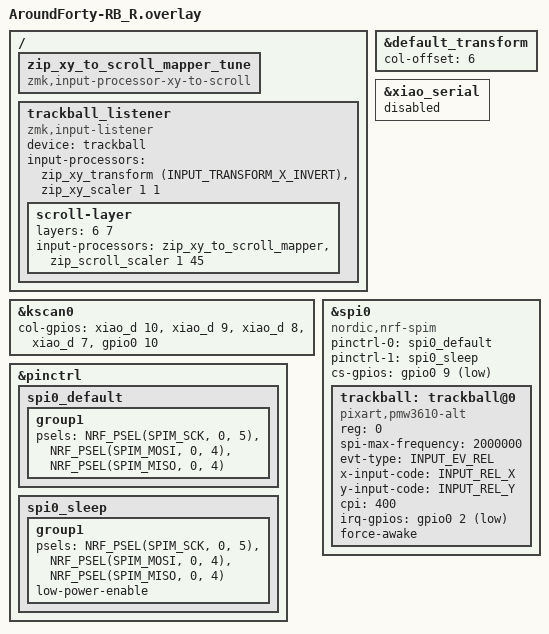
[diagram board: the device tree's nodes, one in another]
#include "AroundForty-RB.dtsi"
#include <dt-bindings/zmk/pointing.h>
#include <dt-bindings/zmk/input_transform.h>
#include <input/processors.dtsi>
#include <zephyr/dt-bindings/input/input-event-codes.h>

&default_transform {
    col-offset = <6>;
};

&kscan0 {
    col-gpios
        = <&xiao_d 10 GPIO_ACTIVE_HIGH>
        , <&xiao_d  9 GPIO_ACTIVE_HIGH>
        , <&xiao_d  8 GPIO_ACTIVE_HIGH>
        , <&xiao_d  7 GPIO_ACTIVE_HIGH>
        , <&gpio0  10 GPIO_ACTIVE_HIGH>
        ;
};

/ {
    /*
     * 将来スクロール方向を変えたくなった時用（X/Y個別反転）
     * ※今は使わない（scroll-layer側はデフォルト mapper を使用）
     */
    zip_xy_to_scroll_mapper_tune: zip_xy_to_scroll_mapper_tune {
        compatible = "zmk,input-processor-xy-to-scroll";
        #input-processor-cells = <0>;

        /* 縦スクロール方向を反転（必要になったら有効化） */
        // scroll-y-invert;

        /* 横スクロール方向を反転（必要になったら有効化） */
        // scroll-x-invert;
    };

    trackball_listener: trackball_listener {
        compatible = "zmk,input-listener";
        device = <&trackball>;

        /* 通常カーソル用 input processors（要素はカンマ区切り） */
        input-processors =
            <&zip_xy_transform (INPUT_TRANSFORM_X_INVERT)>,
            /* ▼ カーソル速度のXとYの速度調整。CPIとはまた別 */
            <&zip_xy_scaler 1 1>;

            /* ▼ AutoMouseLayerを無効化しているのでコメント外せば有効になる */
            /* ▼ 有効の場合はLayer9/300msの設定 */
            /* <&zip_temp_layer 9 300>; */

        /* スクロール用（レイヤー 6 と 7） */
        scroll-layer {
            layers = <6 7>;

            input-processors =
                /* ▼ 現在：向きは変えない（デフォルト） */
                <&zip_xy_to_scroll_mapper>,

                /* ▼ 将来：向きを変えるなら上を消してこっちに切替 */
                /* <&zip_xy_to_scroll_mapper_tune>, */

                /* ▼ スクロール速度を遅めに設定 */
                <&zip_scroll_scaler 1 45>;
        };
    };
};

&pinctrl {
    spi0_default: spi0_default {
        group1 {
            psels = <NRF_PSEL(SPIM_SCK,  0, 5)>,
                    <NRF_PSEL(SPIM_MOSI, 0, 4)>,
                    <NRF_PSEL(SPIM_MISO, 0, 4)>;
        };
    };

    spi0_sleep: spi0_sleep {
        group1 {
            psels = <NRF_PSEL(SPIM_SCK,  0, 5)>,
                    <NRF_PSEL(SPIM_MOSI, 0, 4)>,
                    <NRF_PSEL(SPIM_MISO, 0, 4)>;
            low-power-enable;
        };
    };
};

&xiao_serial { status = "disabled"; };

&spi0 {
    status = "okay";
    compatible = "nordic,nrf-spim";
    pinctrl-0 = <&spi0_default>;
    pinctrl-1 = <&spi0_sleep>;
    pinctrl-names = "default", "sleep";
    cs-gpios = <&gpio0 9 GPIO_ACTIVE_LOW>;

    trackball: trackball@0 {
        status = "okay";
        compatible = "pixart,pmw3610-alt";
        reg = <0>;
        spi-max-frequency = <2000000>;
        evt-type = <INPUT_EV_REL>;
        x-input-code = <INPUT_REL_X>;
        y-input-code = <INPUT_REL_Y>;
        cpi = <400>;
        irq-gpios = <&gpio0 2 (GPIO_ACTIVE_LOW | GPIO_PULL_UP)>;
        force-awake;
    };
};
